# Polarfire SoC register map
Vendor: Microchip; File version: 1.0
CPU: Microchip PolarFire SoC 1.0, little endian
Registers are 32-bit, read-write, reset 0x0 unless marked. A register's access mark holds for its fields unless they carry their own. Offsets are from the block's base; [hi:lo] are bit positions; {n}, {i} and the like mark numbered series; 'fields as' and 'values as' point back to an identical list.

## GEM_A_LO (part 5 of 8) — GEM_A_LO Controller
Base 0x20110000
Same registers: GEM_B_LO 0x20112000, GEM_A_HI 0x28110000, GEM_B_HI 0x28112000
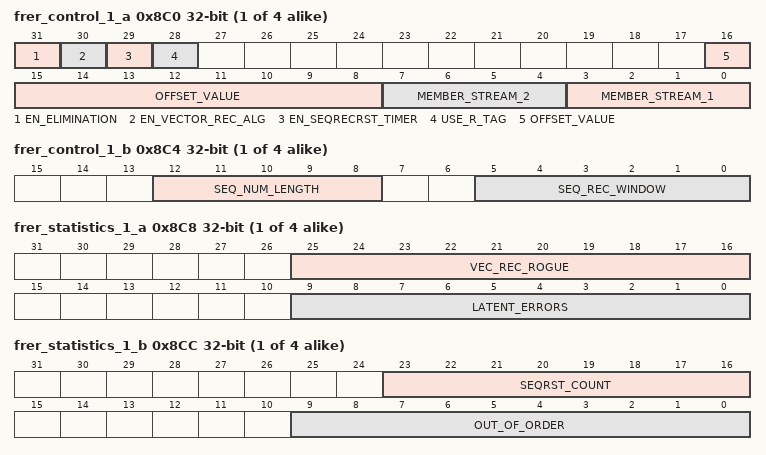
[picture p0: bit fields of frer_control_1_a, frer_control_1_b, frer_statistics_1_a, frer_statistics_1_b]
{0x8B0+0x10*i} frer_control_{i}_a (i=1..4) — FRER control register A
  [31] EN_ELIMINATION — Enable 802.1CB elimination of received frames
  [30] EN_VECTOR_REC_ALG — Enable 802.1CB vector recovery algorithm, : 0 enables the match recovery algorithm, : 1 enables the vector recovery algorithm, :This bit should only be changed when bit 31 en_elimination is low
  [29] EN_SEQRECRST_TIMER — Enable 802.1CB sequence recovery reset timer - this bit may be changed when bit 31 en_elimination is low
  [28] USE_R_TAG — Set to one to use redundancy tag to identify sequence number otherwise use offset value to identify bottom of sequence number - this bit should only be changed when bit 31 en_elimination is low
  [16:8] OFFSET_VALUE — Offset value in bytes from the start packet delimiter to the most significant byte of the 802.1CB sequence number - 9 bits allow a maximum value of 511 - allowing a TCP sequence number to be used with IPv6 - this bit should only be changed when en_elimination is low
  [7:4] MEMBER_STREAM_2 — Pointer to screener type 2 register used for member stream identification. The member stream 1 and 2 values may be programmed to identical values. - this bit should only be changed when en_elimination is low
  [3:0] MEMBER_STREAM_1 — Pointer to screener type 2 register used for member stream identification. The member stream 1 and 2 values may be programmed to identical values. - this bit should only be changed when en_elimination is low
{0x8B4+0x10*i} frer_control_{i}_b (i=1..4) — FRER control register B. This register has default values where the sequence number length defaults to 16 and the vector recovery window defaults to the size of the history vector. It is not expected that the user will need to change these default values.
  [12:8] SEQ_NUM_LENGTH — Number of significant bits of the 802.1CB sequence number. The value 0x00 or numbers greater than 16 bits are equivalent to 16, but the number written will still be read back if it is greater than 16. If a value of less than 16 is written, then the sequence recovery algorithm will only consider that number of LSBs of the sequence number. The minimum size of seq_num_length has to be such that 2^seq_num_len is at least 2xgem_seq_history_len otherwise the vector recovery algorithm will not work correctly - this bit should only be changed when en_elimination is low
  [5:0] SEQ_REC_WINDOW — Vector recovery window, defines the window size used by the vector recovery algorithm to determine whether to reject a packet. Six bits allow a window size of 63, for effective operation of FRER users should not write a value greater than the gem_seq_history_len configuration define, a value of zero means the entire history vector is used - this bit should only be changed when en_elimination is low.
{0x8B8+0x10*i} frer_statistics_{i}_a ro (i=1..4) — FRER statistics register A. This register is cleared on a read and does not roll over if its maximum value is reached.
  [25:16] VEC_REC_ROGUE rw — Count of number of frames dropped by the vector recovery algorithm for being out of range
  [9:0] LATENT_ERRORS rw — Count of sequence numbers seen without a duplicate. The latent error count is updated when a frame is dropped from the history vector. So the update only happens after a new frame is received.
{0x8BC+0x10*i} frer_statistics_{i}_b ro (i=1..4) — FRER statistics register B. This register is cleared on a read and does not roll over if its maximum value is reached.
  [23:16] SEQRST_COUNT rw — Count of number of times the sequence recovery reset timer decrements to zero.
  [9:0] OUT_OF_ORDER rw — Count of out of order sequence numbers received. Incremented when a frame is accepted but the sequence number is not +1 of the highest stored value.
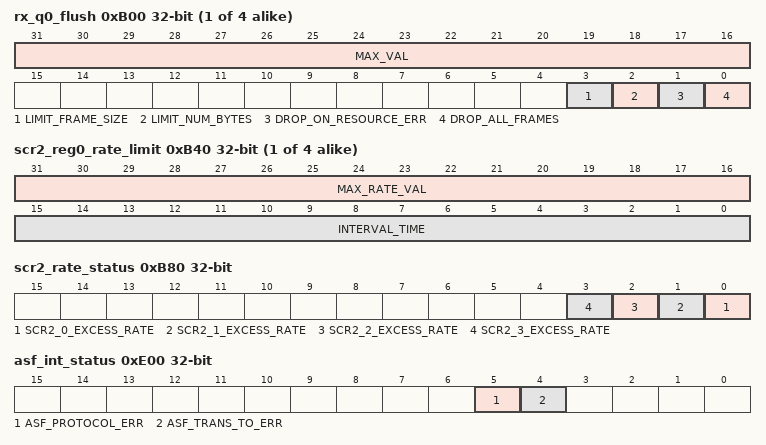
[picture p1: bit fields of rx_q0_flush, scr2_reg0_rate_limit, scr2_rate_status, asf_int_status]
{0xB00+4i} rx_q{i}_flush (i=0..3) — Receive Queue flush register. This register defines the traffic policing mode of operation. Each mode can be set simultaneously with the exception of bits 2 and 3, which are exclusive. If bits 2 and 3 are both set then only bit 3 is treated as active.
  [31:16] MAX_VAL — This 16 bit vector is used when either bit 2 or 3 of this register is asserted. Refer to the description in those bits for details.
  [3] LIMIT_FRAME_SIZE — When set max_val (bits 31:16) indicates the maximum frame-length in bytes that may be received. Frames exceeding this length will be dropped. This traffic policing function is relevant to the 802.1Qci standard which specifies stream filtering based on a maximum SDU (service data unit) size.
  [2] LIMIT_NUM_BYTES — When set, the number of 128 byte chunks of data received for this queue and already stored in the SRAM awaiting DMA memory writes cannot exceed max_val (bits 31:16).
  [1] DROP_ON_RESOURCE_ERR — When set, if a free DMA descriptor for this queue cannot be obtained (also referred to as lack of descriptor resource and occurs when the software either cannot free up descriptors quickly enough to meet the receive traffic rate or has deliberately decided not to free any descriptors), all new frames received on this queue will be automatically discarded.
  [0] DROP_ALL_FRAMES — When set, all frames on this queue will be dropped.
{0xB40+4i} scr2_reg{i}_rate_limit (i=0..3) — Screener type 2 maximum rate register. This register defines the maximum receive rate for the corresponding type 2 screener. This is a traffic policing function and is relevant to the 802.1Qci standard. If the maximum rate is exceeded all frames matched by the corresponding type 2 screener will be discarded until the receive rate falls below the specified value.
  [31:16] MAX_RATE_VAL — This is the maximum number of bytes this screener is permitted to match in the programmed interval time.
  [15:0] INTERVAL_TIME — If during the interval time the total number of bytes of received frames matched by the screener exceeds max_rate_val then the current frame and frames subsequently matched will dropped until an interval time passes where max_rate_val is not exceeded. If this value is set to zero, then no rate limiting will be performed. The interval time is specified in units of 64 rx_clk periods.
0xB80 scr2_rate_status ro — Screener rate limit exceeded status register. For each screener type 2 register configured a status bit will be set and cleared on read if the maximum receive rate is exceeded.
  [n] SCR2_{n}_EXCESS_RATE rw (n=0..3) — Set to 1 if screeners rate limiting mechanism has been triggered
0xE00 asf_int_status — ASF Interrupt Status Register. This register indicates the source of ASF interrupts. The corresponding bit in the mask register must be clear for a bit to be set. If any bit is set in this register the asf_fatal or asf_nonfatal signal will be asserted. Writing to either raw or masked status registers, clear both registers. For test purposes, trigger signal interrupt event by writing to the ASF interrupt status test register.
  [5] ASF_PROTOCOL_ERR — Protocol error interrupt
  [4] ASF_TRANS_TO_ERR — Transaction timeouts error interrupt
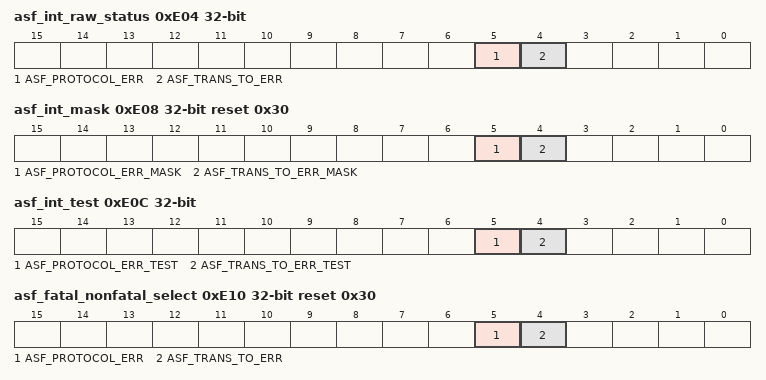
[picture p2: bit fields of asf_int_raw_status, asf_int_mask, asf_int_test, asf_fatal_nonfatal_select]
0xE04 asf_int_raw_status — ASF Interrupt Raw Status Register. A bit set in this raw register indicates a source of ASF fault in the corresponding feature. Writing to either raw or masked status registers, clear both registers. For test purposes, trigger signal interrupt event by writing to the ASF interrupt status test register.
  fields as asf_int_status
0xE08 asf_int_mask reset 0x30 — The ASF interrupt mask register indicating which interrupt bits in the ASF interrupt status register are masked. All bits are set at reset. Clear the individual bit to enable the corresponding interrupt.
  [5] ASF_PROTOCOL_ERR_MASK — Mask bit for protocol error interrupt.
  [4] ASF_TRANS_TO_ERR_MASK — Mask bit for transaction timeouts error interrupt.
0xE0C asf_int_test — The ASF interrupt test register emulate hardware even. Write one to individual bit to trigger single event in (masked and raw) status registers according to mask and will generate interrupt accordingly.
  [5] ASF_PROTOCOL_ERR_TEST — Test bit for protocol error interrupt.
  [4] ASF_TRANS_TO_ERR_TEST — Test bit for transaction timeouts error interrupt.
0xE10 asf_fatal_nonfatal_select reset 0x30 — The fatal or non-fatal interrupt register selects whether a fatal (asf_int_fatal) or non-fatal (asf_int_nonfatal) interrupt is triggered. If the bit of the event will be set to one then fatal interrupt (asf_int_fatal) will be triggered. Otherwise the non-fatal interrupt (asf_int_nonfatal) will be triggered.
  [5] ASF_PROTOCOL_ERR — Enable protocol error interrupt as fatal.
  [4] ASF_TRANS_TO_ERR — Enable transaction timeouts error interrupt as fatal.
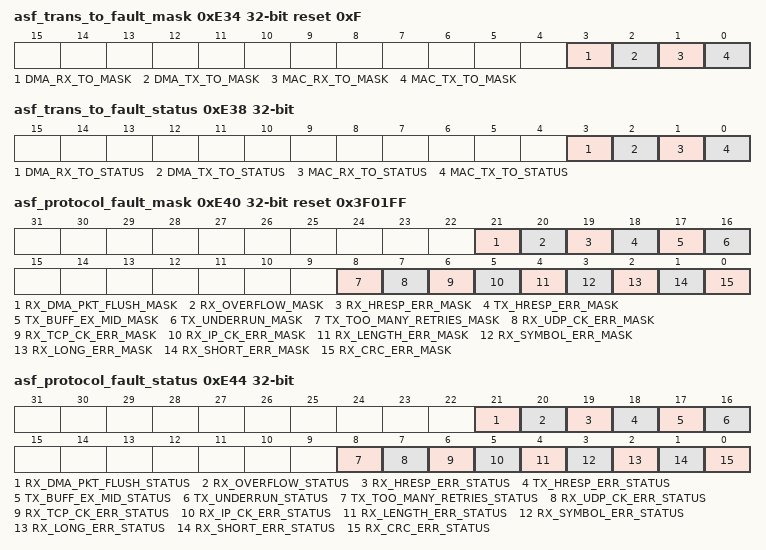
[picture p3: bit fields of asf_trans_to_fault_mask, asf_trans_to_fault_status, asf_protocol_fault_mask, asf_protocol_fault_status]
0xE34 asf_trans_to_fault_mask reset 0xF — Control register to mask out ASF transaction timeout faults from triggering interrupts. On reset, all bits are set to mask out all sources. Clear the corresponding bit to enable the interrupt source.
  [3] DMA_RX_TO_MASK — Mask register for DMA RX lockup detection.
  [2] DMA_TX_TO_MASK — Mask register for DMA TX lockup detection.
  [1] MAC_RX_TO_MASK — Mask register for MAC RX lockup detection.
  [0] MAC_TX_TO_MASK — Mask register for MAC TX lockup detection.
0xE38 asf_trans_to_fault_status — Status register for transaction timeouts fault. If a fault occurs the revelant status bit will be set to 1. Each bit can be cleared by software writing 1 to each bit.
  [3] DMA_RX_TO_STATUS — Status bit for DMA RX lockup detection.
  [2] DMA_TX_TO_STATUS — Status bit for DMA TX lockup detection.
  [1] MAC_RX_TO_STATUS — Status bit for MAC RX lockup detection.
  [0] MAC_TX_TO_STATUS — Status bit for MAC TX lockup detection.
0xE40 asf_protocol_fault_mask reset 0x3F01FF — Control register to mask out ASF Protocol faults from triggering interrupts. On reset, all bits are set to mask out all sources. Clear the corresponding bit to enable the interrupt source.
  [21] RX_DMA_PKT_FLUSH_MASK — Mask bit for RX packet was flushed from the DMA.
  [20] RX_OVERFLOW_MASK — Mask bit for DMA buffer overflow and packet was dropped.
  [19] RX_HRESP_ERR_MASK — Mask bit for DMA hresp error (AHB only).
  [18] TX_HRESP_ERR_MASK — Mask bit for DMA hresp error (AHB only).
  [17] TX_BUFF_EX_MID_MASK — Mask bit for Transmit buffers exhausted before end of packet.
  [16] TX_UNDERRUN_MASK — Mask bit for Transmit DMA underrun occurred.
  [8] TX_TOO_MANY_RETRIES_MASK — Mask bit for too many retry attempts after collision error (half duplex only).
  [7] RX_UDP_CK_ERR_MASK — Mask bit for RX packet UDP checksum error.
  [6] RX_TCP_CK_ERR_MASK — Mask bit for RX packet TCP checksum error.
  [5] RX_IP_CK_ERR_MASK — Mask bit for RX packet IP checksum error.
  [4] RX_LENGTH_ERR_MASK — Mask bit for RX packet with length field error.
  [3] RX_SYMBOL_ERR_MASK — Mask bit for RX packet with symbol errors.
  [2] RX_LONG_ERR_MASK — Mask bit for RX packet too long.
  [1] RX_SHORT_ERR_MASK — Mask bit for RX packet too short.
  [0] RX_CRC_ERR_MASK — Mask bit for RX packet with bad CRC.
0xE44 asf_protocol_fault_status — Status register for protocol faults. If a fault occurs the revelant status bit will be set to 1. Each bit can be cleared by software writing 1 to each bit
  [21] RX_DMA_PKT_FLUSH_STATUS — Status bit for RX packet was flushed from the DMA.
  [20] RX_OVERFLOW_STATUS — Status bit for DMA buffer overflow and packet was dropped.
  [19] RX_HRESP_ERR_STATUS — Status bit for DMA hresp error (AHB only).
  [18] TX_HRESP_ERR_STATUS — Status bit for DMA hresp error (AHB only).
  [17] TX_BUFF_EX_MID_STATUS — Status bit for Transmit buffers exhausted before end of packet.
  [16] TX_UNDERRUN_STATUS — Status bit for Transmit DMA underrun occurred.
  [8] TX_TOO_MANY_RETRIES_STATUS — Status bit for too many retry attempts after collision error (half duplex only).
  [7] RX_UDP_CK_ERR_STATUS — Status bit for RX packet UDP checksum error.
  [6] RX_TCP_CK_ERR_STATUS — Status bit for RX packet TCP checksum error.
  [5] RX_IP_CK_ERR_STATUS — Status bit for RX packet IP checksum error.
  [4] RX_LENGTH_ERR_STATUS — Status bit for RX packet with length field error.
  [3] RX_SYMBOL_ERR_STATUS — Status bit for RX packet with symbol errors.
  [2] RX_LONG_ERR_STATUS — Status bit for RX packet too long.
  [1] RX_SHORT_ERR_STATUS — Status bit for RX packet too short.
  [0] RX_CRC_ERR_STATUS — Status bit for RX packet with bad CRC.
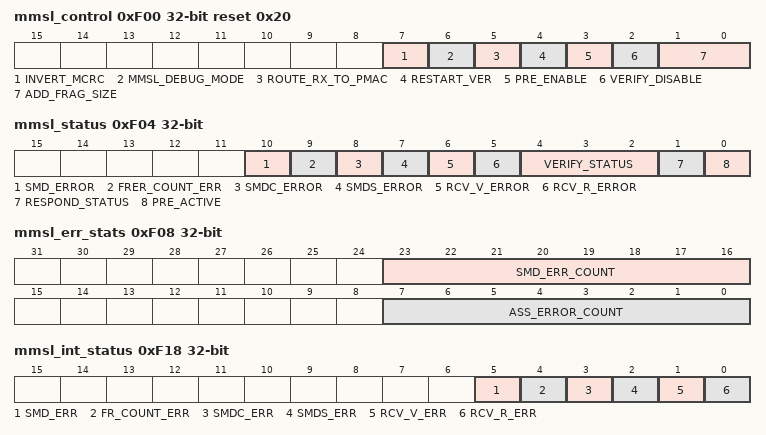
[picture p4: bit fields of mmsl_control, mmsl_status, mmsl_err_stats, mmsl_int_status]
0xF00 mmsl_control reset 0x20 — MMSL Control Register. This register contains the control bits for the 802.3br MAC Merge Sublayer (MMSL)
  [7] INVERT_MCRC — When set to 1 the generated mCRC will be inverted before transmission and the receive path will require the received mCRC to be inverted. Keep this bit 0 for normal operation.
  [6] MMSL_DEBUG_MODE — This bit is used for test purposes only. When set, the verify_timer counter is sped up by a factor of 256. The main effect of this is that about 40 us are spent waiting for a response packet rather than 10 ms.
  [5] ROUTE_RX_TO_PMAC — When set, the MMSL routes all received traffic to the pMAC rather than the eMAC when pre_active is 0 in the MMSL status register.
  [4] RESTART_VER — Write a one to this bit to initiate the verification procedure. Writing a one to this bit has no effect if any of the following are true: pre_enable is zero, verify_disable is one or the verification procedure is already in progress. If pre-emption is active, route_rx_to_pmac should be set to zero before writing to the restart_ver bit otherwise express MAC frames will be sent to the pMAC and will be lost if they are interspersed between pMAC frame fragments. This bit always returns zero when read.
  [3] PRE_ENABLE — This bit is for enabling/disabling the pre-emption operation. If set to zero pre-emption will not occur and verify mpackets will not be responded to or sent. If verify_disable is zero the verification process starts when this bit is written with one and pre-emption can occur once the verification process completes. If verify_disable is high pre-emption can occur as soon as this bit is set. If this bit is reset to zero from one and pre-emption is in progress, then pre-emption will complete and no more pre-emption will occur.
  [2] VERIFY_DISABLE — This bit is for enabling/disabling the verification procedure that determine whether the link partner can support 802.3br. If disabled the link partner will not be verified and pre-emption is enabled as soon as pre_enable is set to one. Verify mpackets are responded to regardless of whether this bit is set. This bit is static and must be valid before pre_enable is set.
  [1:0] ADD_FRAG_SIZE — This bit field determines the minimum number of bytes which the pMAC sends before pre-emption is allowed. The vector is encoded as follows:, :, : 0: 64 bytes, : 1: 128 bytes, : 2: 192 bytes, : 3: 256 bytes, :, :These bits are static and must be valid before pre_enable is set.
0xF04 mmsl_status ro — MMSL Status Register. This register contains the MMSL status bits.
  [10] SMD_ERROR rw — This bit is set to 1 if an illegal SMD is received, that is if the SMD was not an Express, Verify, Response, Start Preemptible or Continuation Preemptible SMD.
  [9] FRER_COUNT_ERR rw — This bit is set to 1 if a frame count error occurs, that is if the SMD-C received indicates a different frame count than expected (i.e. the fragment belongs to another frame and not to the Start packet already received before this) or if a Fragment error happened, which means the field following the SMD-C received was encoding a different fragment count than it was supposed to be
  [8] SMDC_ERROR rw — This bit is set to 1 if an SMD-C is received when waiting for an SMD-S
  [7] SMDS_ERROR rw — This is set to 1 if an SMD-S is received when waiting for an SMD-C
  [6] RCV_V_ERROR rw — This bit is set to 1 if the verification m-packet received is incorrect
  [5] RCV_R_ERROR rw — This bit is set to 1 if the response m-packet received is incorrect. If this occurs the verification process fails.
  [4:2] VERIFY_STATUS — These bits indicate the state of the verification state machine:, : 3'b000 - INIT_VERIFICATION, : 3'b001 - VERIFICATION_IDLE, : 3'b010 - SEND_VERIFY, : 3'b011 - WAIT_FOR_RESPONSE, : 3'b100 - VERIFIED, : 3'b101 - VERIFY_FAIL
  [1] RESPOND_STATUS — This bit indicates the state of the respond state machine:, : 0 - R_IDLE, : 1 - SEND_RESPOND
  [0] PRE_ACTIVE — This bit is set to one if pre-emption capability is active. It is set to one after the verification process completes, or if verify_disable is one when pre_enable is set to one.
0xF08 mmsl_err_stats ro — MMSL error statistics register. This register contains error counters for the MMSL. It is cleared on a read and does not roll if its maximum value is reached.
  [23:16] SMD_ERR_COUNT rw — A count of received MAC frames/MAC frame fragments rejected due to unknown SMD value or arriving with an SMD-C when no frame is in progress.
  [7:0] ASS_ERROR_COUNT rw — A count of MAC frames with reassembly errors. The counter is incremented by one every time the ASSEMBLY_ERROR state in the Receive Processing State Diagram is entered.
0xF0C mmsl_ass_ok_count ro — MMSL frames reassembled OK register. This register contains a count of MAC frames that were successfully reassembled and delivered to MAC. It is cleared on a read and does not roll if its maximum value is reached.
  [16:0] ASS_OK_COUNT rw — A count of MAC frames that were successfully reassembled and delivered to the MAC.
0xF10 mmsl_frag_count_rx ro — MMSL fragments received register. This register contains a count of the number of additional mPackets received due to preemption. It is cleared on a read and does not roll if its maximum value is reached.
  [16:0] FRAG_COUNT_RX rw — A count of the number of additional mPackets received due to preemption.
0xF14 mmsl_frag_count_tx ro — MMSL fragments transmitted register. This register contains a count of the number of additional mPackets transmitted due to preemption. It is cleared on a read and does not roll if its maximum value is reached.
  [16:0] FRAG_COUNT_TX rw — A count of the number of additional mPackets transmitted due to preemption.
0xF18 mmsl_int_status — MMSL Interrupt Status Register. This register indicates the source of an MMSL interrupt. The corresponding bit in the MMSL interrupt mask register must be clear for a bit to be set. If any bit is set in this register the ethernet_int signal will be asserted. For test purposes each bit can be set or reset by writing to the interrupt mask register. All interrupt status bits are reset to zero on read if the 'gem_irq_read_clear define is set otherwise a one is written to the appropriate bit in order to clear it. In this mode reading has no effect on the status of the bit.
  [5] SMD_ERR — Indicates an illegal SMD was received, that is the SMD was not an Express, Verify, Response, Start Pre-emptible or Continuation Pre-emptible SMD.
  [4] FR_COUNT_ERR — Indicates a Frame Count error happened, that is the SMD-C received indicates a different frame count than expected (i.e. the fragment belongs to another frame and not to the Start packet already received before this) or if a Fragment error happened, which means the field following the SMD-C received was encoding a different fragment count than it was supposed to be
  [3] SMDC_ERR — Indicates an SMD-C was received when waiting for an SMD-S
  [2] SMDS_ERR — Indicates an SMD-S was received when waiting for an SMD-C
  [1] RCV_V_ERR — Indicates an incorrect verification m-packet was received
  [0] RCV_R_ERR — Indicates an incorrect response m-packet was received. If this occurs the verification process fails.
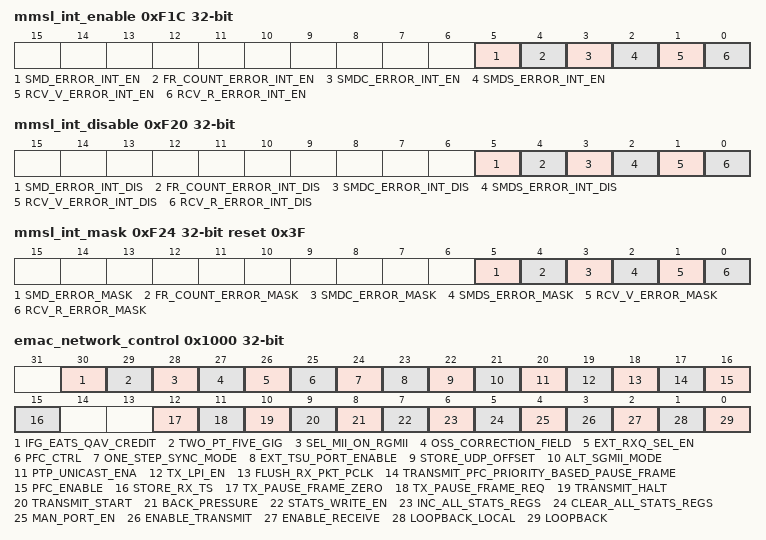
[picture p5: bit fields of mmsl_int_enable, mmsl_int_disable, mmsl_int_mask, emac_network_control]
0xF1C mmsl_int_enable — MMSL Interrupt Enable Register. At reset all interrupts are disabled. Writing a one to the relevant bit location enables the required interrupt. This register is write only and when read will return zero.
  [5] SMD_ERROR_INT_EN — Enable SMD error interrupt.
  [4] FR_COUNT_ERROR_INT_EN — Enable frame count error interrupt.
  [3] SMDC_ERROR_INT_EN — Enable SMD-C error interrupt.
  [2] SMDS_ERROR_INT_EN — Enable SMD-S error interrupt.
  [1] RCV_V_ERROR_INT_EN — Enable verify packet received error interrupt.
  [0] RCV_R_ERROR_INT_EN — Enable response packet received error interrupt.
0xF20 mmsl_int_disable — MMSL Interrupt Disable Register. Writing a 1 to the relevant bit location disables that particular interrupt. This register is write only and when read will return zero.
  [5] SMD_ERROR_INT_DIS — Disable SMD error interrupt.
  [4] FR_COUNT_ERROR_INT_DIS — Disable frame count error interrupt.
  [3] SMDC_ERROR_INT_DIS — Disable SMD-C error interrupt.
  [2] SMDS_ERROR_INT_DIS — Disable SMD-S error interrupt.
  [1] RCV_V_ERROR_INT_DIS — Disable verify packet received error interrupt.
  [0] RCV_R_ERROR_INT_DIS — Disable response packet received error interrupt.
0xF24 mmsl_int_mask ro reset 0x3F — MMSL Interrupt Mask Register. The interrupt mask register is a read only register indicating which interrupts are masked. All bits are set at reset and can be reset individually by writing to the interrupt enable register or set individually by writing to the interrupt disable register. Having separate address locations for enable and disable saves the need for performing a read modify write when updating the interrupt mask register. For test purposes there is a write-only function to this register that allows the bits in the interrupt status register to be set or cleared, regardless of the state of the mask register.
  [5] SMD_ERROR_MASK — Mask bit for SMD error interrupt.
  [4] FR_COUNT_ERROR_MASK — Mask bit for frame count error interrupt.
  [3] SMDC_ERROR_MASK — Mask bit for SMD-C error interrupt.
  [2] SMDS_ERROR_MASK — Mask bit for SMD-S error interrupt.
  [1] RCV_V_ERROR_MASK — Mask bit for verify packet received error interrupt.
  [0] RCV_R_ERROR_MASK — Mask bit for response packet received error interrupt.
0x1000 emac_network_control — The network control register contains general MAC control functions for both receiver and transmitter.
  [30] IFG_EATS_QAV_CREDIT — Setting this bit high modifies the CBS algorithm so the IFG/IPG associated with a transmit frame counts towards its 802.1Qav credit.
  [29] TWO_PT_FIVE_GIG — 2.5G operation selected - setting this bit high drives the speed_mode[3] top level output pin high and also adjusts the link timer in the PCS auto-negotiation block to ensure it delivers 10ms for 2500BASE-X and 1.6ms in SGMII mode, and also ensures int_moderation counts 800ns periods with the speeded up MAC clocks.
  [28] SEL_MII_ON_RGMII — If the RGMII interface being used set this bit high to configure the interface for MII operation (in 802.3br configurations this bit has no effect for the eMAC).
  [27] OSS_CORRECTION_FIELD — 1588 One Step Correction Field Update. Set this bit high to enable updating the correction field of PTP 1588 version 2 sync frames by adding current TSU timer value.
  [26] EXT_RXQ_SEL_EN — Enable external selection of receive queue. When this bit is high the ext_match1, ext_match2, ext_match3 and ext_match4 inputs will determine which receive queue a frame is routed to. This will be the case regardless of the state of the external address match enable bit 9 of the network config register. Note that receive frames will be dropped unless they are matched by the internal frame filtering functionality. If the external address match enable bit 9 in the network config register is set frames may be matched by an external address match filter as long as one of the ext_match1, ext_match2, ext_match3 and ext_match4 inputs is asserted early enough. When set ext_rxq_sel_en takes precedence over the existing screener functionality. This bit is only relevant if priority queuing is configured.
  [25] PFC_CTRL — Enable multiple PFC pause quantums, one per pause priority.
  [24] ONE_STEP_SYNC_MODE — 1588 One Step Sync Mode. Write 1 to enable. Replace timestamp field in the 1588 header for TX Sync Frames with current TSU timer value.
  [23] EXT_TSU_PORT_ENABLE — External TSU timer port enable (1 = enable) - for the eMAC this should be enabled.
  [22] STORE_UDP_OFFSET — Store UDP / TCP offset to memory. Setting this bit to one will cause the upper 16-bits of the CRC of every received frame to be replaced with the offset from start of frame to the beginning of the UDP or TCP header. The lower 16-bits of the CRC are replaced with zero and reserved for future use. The offset is measured in units of 2 bytes. Set to zero for normal operation.
  [21] ALT_SGMII_MODE — Alternative sgmii mode. If asserted with sgmii_mode in the network control register the ACK bit is driven before ability detect during transfer of status information from the PHY to the MAC.
  [20] PTP_UNICAST_ENA — Enable detection of unicast PTP unicast frames.
  [19] TX_LPI_EN — LPI is supported by the pMAC not the eMAC. Do not set this bit in the eMAC.
  [18] FLUSH_RX_PKT_PCLK — Flush the next packet from the external RX DPRAM. This bit flushes the frame that is the next in line to be pushed out to the AXI interface. Writing one to this bit will only have an effect if the DMA is not currently writing a packet already stored in the DPRAM to memory.
  [17] TRANSMIT_PFC_PRIORITY_BASED_PAUSE_FRAME — Write a one to transmit PFC priority based pause frame. Takes the values stored in the Transmit PFC Pause Register.
  [16] PFC_ENABLE — Enable PFC Priority Based Pause Reception capabilities. Setting this bit will enable PFC negotiation and recognition of priority based pause frames.
  [15] STORE_RX_TS — Store receive time stamp to memory. Setting this bit to one will cause the CRC of every received frame to be replaced with the value of the nanoseconds field of the 1588 timer that was captured as the receive frame passed the message time stamp point (for releases prior to 1p10 bits 31 and 30 of the value written to the CRC field were hardwired to zero, from release 1p10 onwards these bits represent the two least significant seconds bit of the captured timer value). Set to zero for normal operation.
  [12] TX_PAUSE_FRAME_ZERO — Transmit zero quantum pause frame - writing one to this bit causes a pause frame with zero quantum to be transmitted.
  [11] TX_PAUSE_FRAME_REQ — Transmit pause frame - writing one to this bit causes a pause frame to be transmitted.
  [10] TRANSMIT_HALT — Transmit halt - writing one to this bit resets the tx_go variable and halts the dma from reading more transmit frames into the transmit SRAM buffer. Any frames already read into the transmit SRAM will still be transmitted.
  [9] TRANSMIT_START — Start transmission - writing one to this bit starts transmission.
  [8] BACK_PRESSURE — Back pressure if set in 10M or 100M half-duplex mode will force collisions on all received frames. Ignored in gigabit half-duplex mode.
  [7] STATS_WRITE_EN — Write enable for statistics registers - setting this bit to one means the statistics registers can be written for functional test purposes.
  [6] INC_ALL_STATS_REGS — Incremental statistics registers - this bit is write only. Writing a one increments all the statistics registers by one for test purposes.
  [5] CLEAR_ALL_STATS_REGS — Clear statistics registers - this bit is write only. Writing a one clears the statistics registers.
  [4] MAN_PORT_EN — Management port enable - set to one to enable the management port. When zero forces mdio to high impedance state and mdc low.
  [3] ENABLE_TRANSMIT — Transmit enable - when set, it enables the GEM transmitter to send data. When reset transmission will stop immediately, the transmit pipeline and control registers will be cleared and the transmit queue pointer register will reset to point to the start of the transmit descriptor list. This bit needs to be set before bit 9 the start transmission bit. (Setting this bit low resets the transmit queue pointer however reading the transmit queue pointer register through the APB interface may still return an old value until transmission is restarted.)
  [2] ENABLE_RECEIVE — Receive enable - when set, it enables the GEM to receive data. When reset frame reception will stop immediately and the receive pipeline will be cleared. The receive queue pointer register is unaffected.
  [1] LOOPBACK_LOCAL — Loopback local - asserts the loopback_local signal to the system clock generator. Also connects txd to rxd, tx_en to rx_dv and forces full duplex mode. If the GEM configuration contains the PCS then bit 11 of the network configuration register must be set low to disable TBI mode when in internal loopback. rx_clk and tx_clk may malfunction as the GEM is switched into and out of internal loopback. It is important that receive and transmit circuits have already been disabled when making the switch into and out of internal loopback. Local loopback functionality is optional and may not be supported by some instantiations of the GEM.
  [0] LOOPBACK — Loopback - controls the loopback output pin.
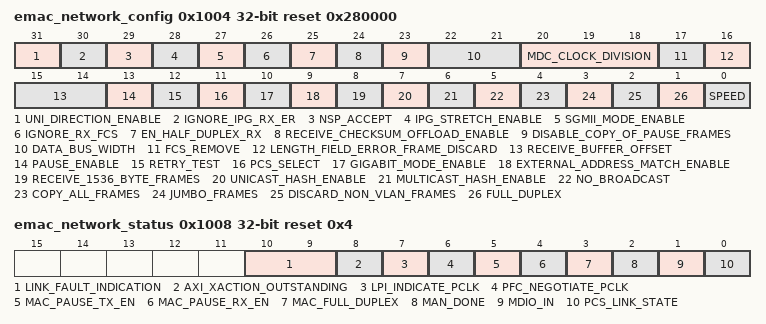
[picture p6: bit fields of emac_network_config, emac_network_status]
0x1004 emac_network_config reset 0x280000 — The network configuration register contains functions for setting the mode of operation for the Gigabit Ethernet MAC.
  [31] UNI_DIRECTION_ENABLE — Uni-direction-enable. When low the PCS will transmit idle symbols if the link goes down. When high the PCS can transmit frame data when the link is down.
  [30] IGNORE_IPG_RX_ER — Ignore IPG rx_er. When set rx_er has no effect on the GEMs operation when rx_dv is low. Set this when using the RGMII wrapper in half-duplex mode.
  [29] NSP_ACCEPT — Receive bad preamble. When set frames with non-standard preamble are not rejected (the first byte of preamble needs to be 55 and the last D5, bytes other than 55 or D5 may be inserted in between).
  [28] IPG_STRETCH_ENABLE — IPG stretch enable - when set the transmit IPG can be increased above 96 bit times depending on the previous frame length using the IPG stretch register.
  [27] SGMII_MODE_ENABLE — SGMII mode enable - changes behaviour of the auto-negotiation advertisement and link partner ability registers to meet the requirements of SGMII and reduces the duration of the link timer from 10 ms to 1.6 ms.
  [26] IGNORE_RX_FCS — Ignore RX FCS - when set frames with FCS/CRC errors will not be rejected. FCS error statistics will still be collected for frames with bad FCS and FCS status will be recorded in frame's DMA descriptor. For normal operation this bit must be set to zero.
  [25] EN_HALF_DUPLEX_RX — Enable frames to be received in half-duplex mode while transmitting.
  [24] RECEIVE_CHECKSUM_OFFLOAD_ENABLE — Receive checksum offload enable - when set, the receive checksum engine is enabled. Frames with bad IP, TCP or UDP checksums are discarded.
  [23] DISABLE_COPY_OF_PAUSE_FRAMES — Disable copy of pause frames - set to one to prevent pause frames being copied to memory. When set, neither control frames with type id 8808, nor pause frames with destination address 010000c28001 are copied to memory, this functionality was enhanced in release 1p09. Note that valid pause frames received will still increment pause statistics and pause the transmission of frames as required.
  [22:21] DATA_BUS_WIDTH — Data bus width - set according to AMBA (AHB/AXI) or external FIFO data bus width. The reset value for this can be changed by defining a new value for gem_dma_bus_width_def in gem_defs. Only valid bus widths may be written if the system is configured to a maximum width less than 128-bits., :00: 32 bit data bus width, :01: 64 bit AMBA (AHB/AXI) data bus width, :10: 128 bit AMBA (AHB/AXI) data bus width, :11: invalid, :Note. The reset value of this field is equal to the gem_dma_bus_width_def define, which is user configurable.
  [20:18] MDC_CLOCK_DIVISION — MDC clock division - set according to pclk speed. These three bits determine the number pclk will be divided by to generate MDC. For conformance with the 802.3 specification, MDC must not exceed 2.5 MHz (MDC is only active during MDIO read and write operations). The reset value for this can be changed by defining a new value for gem_mdc_clock_div in gem_defs.v, :000: divide pclk by 8 (pclk up to 20 MHz), :001: divide pclk by 16 (pclk up to 40 MHz), :010: divide pclk by 32 (pclk up to 80 MHz), :011: divide pclk by 48 (pclk up to 120MHz), :100: divide pclk by 64 (pclk up to 160 MHz), :101: divide pclk by 96 (pclk up to 240 MHz), :110: divide pclk by 128 (pclk up to 320 MHz), :111: divide pclk by 224 (pclk up to 540 MHz)., :Note. The reset value of this field is equal to the gem_mdc_clock_div define, which is user configurable.
  [17] FCS_REMOVE — FCS remove - setting this bit will cause received frames to be written to memory without their frame check sequence (last 4 bytes). The frame length indicated will be reduced by four bytes in this mode.
  [16] LENGTH_FIELD_ERROR_FRAME_DISCARD — Length field error frame discard - setting this bit causes frames with a measured length shorter than the extracted length field (as indicated by bytes 13 and 14 in a non-VLAN tagged frame) to be discarded. This only applies to frames with a length field less than 0x0600.
  [15:14] RECEIVE_BUFFER_OFFSET — Receive buffer offset - indicates the number of bytes by which the received data is offset from the start of the receive buffer. Note that when the define gem_pbuf_rsc has been set then these bits cannot be used.
  [13] PAUSE_ENABLE — Pause enable - when set, transmission will pause if a non-zero 802.3 classic pause frame is received and PFC has not been negotiated.
  [12] RETRY_TEST — Retry test - must be set to zero for normal operation. If set to one the backoff between collisions will always be one slot time. Setting this bit to one helps test the too many retries condition. Also used in the pause frame tests to reduce the pause counter's decrement time from 512 bit times, to every rx_clk cycle.
  [11] PCS_SELECT — PCS select - selects between MII/GMII and TBI. Must be set for SGMII operation., :0: GMII/MII interface enabled, TBI disabled, :1: TBI enabled, GMII/MII disabled, :(in 802.3br configurations this bit must be set identically in the eMAC and pMAC)
  [10] GIGABIT_MODE_ENABLE — Gigabit mode enable - setting this bit configures the GEM for 1000 Mbps operation., :0: 10/100 operation using MII or TBI interface, :1: Gigabit operation using GMII or TBI interface, :(in 802.3br configurations this bit must be set identically in the eMAC and pMAC)
  [9] EXTERNAL_ADDRESS_MATCH_ENABLE — External address match enable - when set the external address match interface can be used to copy frames to memory.
  [8] RECEIVE_1536_BYTE_FRAMES — Receive 1536 byte frames - setting this bit means the GEM will accept frames up to 1536 bytes in length. Normally the GEM would reject any frame above 1518 bytes.
  [7] UNICAST_HASH_ENABLE — Unicast hash enable - when set, unicast frames will be accepted when the 6 bit hash function of the destination address points to a bit that is set in the hash register.
  [6] MULTICAST_HASH_ENABLE — Multicast hash enable - when set, multicast frames will be accepted when the 6 bit hash function of the destination address points to a bit that is set in the hash register.
  [5] NO_BROADCAST — No broadcast - when set to logic one, frames addressed to the broadcast address of all ones will not be accepted.
  [4] COPY_ALL_FRAMES — Copy all frames - when set to logic one, all valid frames will be accepted.
  [3] JUMBO_FRAMES — Jumbo frames - set to one to enable jumbo frames up to 'gem_jumbo_max_length bytes to be accepted. The default length is 10,240 bytes.
  [2] DISCARD_NON_VLAN_FRAMES — Discard non-VLAN frames - when set only VLAN tagged frames will be passed to the address matching logic.
  [1] FULL_DUPLEX — Full duplex - if set to logic one, the transmit block ignores the state of collision and carrier sense and allows receive while transmitting. Also controls the half_duplex pin.
  [0] SPEED — Speed - set to logic one to indicate 100Mbps operation, logic zero for 10Mbps. The value of this pin is reflected on the speed_mode[0] output pin (in 802.3br configurations this bit has no effect for the eMAC).
0x1008 emac_network_status ro reset 0x4 — The network status register returns status information with respect to the PHY management MDIO interface, the PCS, priority flow control, LPI and other status.
  [10:9] LINK_FAULT_INDICATION — For 2.5GBASE-X operation these two bits return the state of link_fault in the LFSM defined in Figure 46-11 of IEEE 802.3:, : 00 - OK, : 01 - local fault, : 10 - remote fault, : 11 - link interruption, :If the link fault state machine is not enabled (by setting the 2.5G, AN enable, uni directional enable and tbi control bits) these two bits are set to zero.
  [8] AXI_XACTION_OUTSTANDING — Outstanding AXI Transactions - This status bit is set when one or more AXI read or write transactions have been issued by the DUT but the responses have not yet been fully collected.
  [7] LPI_INDICATE_PCLK — LPI Indication - Low power idle has been detected on receive. This bit is set when LPI is detected and reset when normal idle is detected. An interrupt is generated when the state of this bit changes.
  [6] PFC_NEGOTIATE_PCLK — Set when PFC Priority Based Pause has been negotiated.
  [5] MAC_PAUSE_TX_EN — PCS auto-negotiation pause transmit resolution.
  [4] MAC_PAUSE_RX_EN — PCS auto-negotiation pause receive resolution.
  [3] MAC_FULL_DUPLEX — PCS auto-negotiation duplex resolution. Set to one if the resolution function determines that both devices are capable of full duplex operation. If zero half-duplex operation is possible as long as bit 0 (PCS link state) is also one.
  [2] MAN_DONE — The PHY management logic is idle (i.e. has completed).
  [1] MDIO_IN — Returns status of the mdio_in pin.
  [0] PCS_LINK_STATE — Returns status of PCS link state. If auto-negotiation is disabled this returns the synchronisation status. If auto-negotiation is enabled it is set in the LINK_OK state as long as a compatible duplex mode is resolved, it is always set in the LINK_OK state in SGMII mode.
